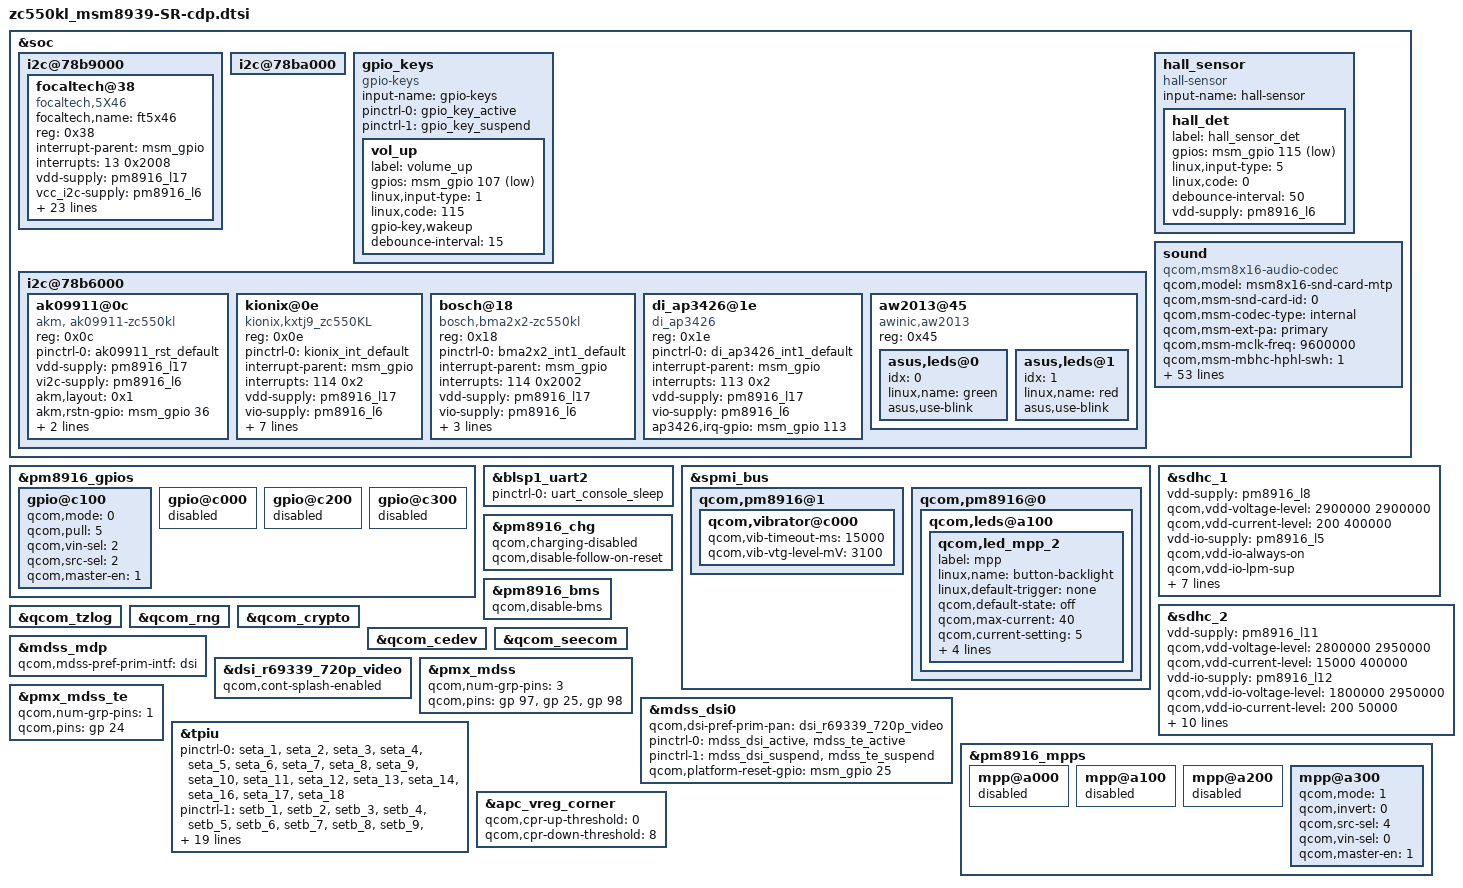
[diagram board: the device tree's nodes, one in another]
/* Copyright (c) 2014-2015, The Linux Foundation. All rights reserved.
 *
 * This program is free software; you can redistribute it and/or modify
 * it under the terms of the GNU General Public License version 2 and
 * only version 2 as published by the Free Software Foundation.
 *
 * This program is distributed in the hope that it will be useful,
 * but WITHOUT ANY WARRANTY; without even the implied warranty of
 * MERCHANTABILITY or FITNESS FOR A PARTICULAR PURPOSE.  See the
 * GNU General Public License for more details.
 */

#include "zc550kl_msm8939-SR-pinctrl.dtsi"
#include "zc550kl_msm8939-SR-camera-sensor-cdp.dtsi"

&soc {
	i2c@78b9000 { /* BLSP1 QUP5 */
		focaltech@38 {
			compatible = "focaltech,5X46";
			focaltech,name = "ft5x46";
			reg = <0x38>;
			interrupt-parent = <&msm_gpio>;
			interrupts = <13 0x2008>;
			vdd-supply = <&pm8916_l17>;
			vcc_i2c-supply = <&pm8916_l6>;
			/* pins used by touchscreen */
			pinctrl-names = "pmx_ts_active","pmx_ts_suspend","pmx_ts_release";
			pinctrl-0 = <&ts_int_active &ts_reset_active>;
			pinctrl-1 = <&ts_int_suspend &ts_reset_suspend>;
			pinctrl-2 = <&ts_release>;
			focaltech,family-id = <0x36>;
			focaltech,reset-gpio = <&msm_gpio 12 0x0>;
			focaltech,irq-gpio = <&msm_gpio 13 0x2008>;
			focaltech,display-coords = <0 0 720 1280>;
			focaltech,panel-coords = <0 0 720 1370>;
			focaltech,button-map= <139 102 158>;
			focaltech,no-force-update;
			focaltech,i2c-pull-up;
			focaltech,group-id = <1>;
			focaltech,hard-reset-delay-ms = <20>;
			focaltech,soft-reset-delay-ms = <200>;
			focaltech,num-max-touches = <5>;
			focaltech,fw-delay-aa-ms = <30>;
			focaltech,fw-delay-55-ms = <30>;
			focaltech,fw-upgrade-id1 = <0x79>;
			focaltech,fw-upgrade-id2 = <0x18>;
			focaltech,fw-delay-readid-ms = <10>;
			focaltech,fw-delay-era-flsh-ms = <2000>;
			focaltech,fw-auto-cal;
			focaltech,ignore-id-check;
		};
	};

	i2c@78ba000 { /* BLSP1 QUP6 */		
		/* ASUS_BSP: wendy_qin  +++*/
		/*nfc-nci@e {
			compatible = "qcom,nfc-nci";
			reg = <0x0e>;
			qcom,irq-gpio = <&msm_gpio 21 0x00>;
			qcom,dis-gpio = <&msm_gpio 20 0x00>;
			qcom,clk-src = "BBCLK2";
			interrupt-parent = <&msm_gpio>;
			interrupts = <21 0>;
			pinctrl-names = "nfc_active","nfc_suspend";
			pinctrl-0 = <&nfc_int_active &nfc_disable_active>;
			pinctrl-1 = <&nfc_int_suspend &nfc_disable_suspend>;
			qcom,clk-gpio = <&pm8916_gpios 2 0>;
			clocks = <&clock_rpm clk_bb_clk2_pin>;
			clock-names = "ref_clk";
		};	*/
		/* ASUS_BSP: wendy_qin  ---*/
	};
	gpio_keys {
		compatible = "gpio-keys";
		input-name = "gpio-keys";
		pinctrl-names = "tlmm_gpio_key_active","tlmm_gpio_key_suspend";
		pinctrl-0 = <&gpio_key_active>;
		pinctrl-1 = <&gpio_key_suspend>;

		vol_up {
			label = "volume_up";
			gpios = <&msm_gpio 107 0x1>;
			linux,input-type = <1>;
			linux,code = <115>;
			gpio-key,wakeup;
			debounce-interval = <15>;
		};
	};

	i2c@78b6000 { /* BLSP1 QUP2 */
		/* ++++  ASUS_BSP alian_shen "add for akm0991" */
		   ak09911@0c {  
		        compatible = "akm, ak09911-zc550kl";
		        reg = <0x0c>;
		        pinctrl-names = "default";
		        pinctrl-0 = <&ak09911_rst_default>;
		        vdd-supply = <&pm8916_l17>;
		        vi2c-supply = <&pm8916_l6>;
		        akm,layout = <0x1>;
		        akm,rstn-gpio = <&msm_gpio 36 0x0>;
		        akm,auto-report ;
		        akm,use-hrtimer ;
		    };    
		    /* -----  ASUS_BSP alian_shen "add for akm0991" */        
        
		/* ++++  ASUS_BSP alian_shen "add for kxtj2-1009" */
		    kionix@0e {
		        compatible = "kionix,kxtj9_zc550KL";
		        reg = <0x0e>;
		        pinctrl-names = "default";
		        pinctrl-0 = <&kionix_int_default>;
		        interrupt-parent = <&msm_gpio>;
		        interrupts = <114 0x2>;
		        vdd-supply = <&pm8916_l17>;
		        vio-supply = <&pm8916_l6>;
		        kionix,min-interval = <10>;
		        kionix,init-interval = <200>;
		        kionix,axis-map-x = <0>;
		        kionix,axis-map-y = <1>;
		        kionix,axis-map-z = <2>;
		        kionix,g-range = <4>;           
		        kionix,res-12bit;
		    };
		    /* -----  ASUS_BSP alian_shen "add for kxtj2-1009" */

		/* ++++  ASUS_BSP alian_shen "add for bma253" */
		bosch@18 { /* Accelerometer sensor */
			compatible = "bosch,bma2x2-zc550kl";
			reg = <0x18>;
			pinctrl-names = "default";
			pinctrl-0 = <&bma2x2_int1_default>;
 			interrupt-parent = <&msm_gpio>;
			interrupts = <114 0x2002>;
 			vdd-supply = <&pm8916_l17>;
 			vio-supply = <&pm8916_l6>;
			bosch,init-interval = <200>;
			bosch,place = <1>;
			bosch,gpio-int1 = <&msm_gpio 114 0x2002>;
			//bosch,gpio-int2 = <&msm_gpio 114 0x2002>; 
 		};
		/* ----  ASUS_BSP alian_shen "add for bma253" */

		 /* ++++  ASUS_BSP alian_shen "add for P/LSensor" */
		    di_ap3426@1e {
		        compatible = "di_ap3426";
		        reg = <0x1e>;
		        pinctrl-names = "default";
		        pinctrl-0 = <&di_ap3426_int1_default>;
		        interrupt-parent = <&msm_gpio>;
		        interrupts = <113 0x2>;//configuration change accordingly such as bus number & pin number
		        vdd-supply = <&pm8916_l17>;
		        vio-supply = <&pm8916_l6>;
		        ap3426,irq-gpio = <&msm_gpio 113 0x02>;
		        /*ap3426,irq-gpio = <&msm_gpio 113 0x2002>;*/
		    };
		    /* ----  ASUS_BSP alian_shen "add for P/LSensor" */
		    
		  aw2013@45 {
            compatible = "awinic,aw2013";
            reg = <0x45>;
            asus,leds@0 {
                status = "okay";
                idx = <0>;
                linux,name = "green";
                //linux,default-trigger = "battery-full";
                asus,use-blink;
             };
            asus,leds@1 {
                status = "okay";
                idx = <1>;
                linux,name = "red";
                //linux,default-trigger = "charging";
                asus,use-blink;
            };
        };

	};
	
	 /*+++  SZ_BSP gauss_li for hall_sersor porting*/
	  hall_sensor {
	    compatible = "hall-sensor";
	    input-name = "hall-sensor";
	    hall_det {
	           label = "hall_sensor_det";
	           gpios = <&msm_gpio 115 0x1>;
	           linux,input-type = <5>;
	           linux,code = <0>;
	           debounce-interval = <50>;
	           vdd-supply = <&pm8916_l6>;
	        };  
	};
	/*---      SZ_BSP gauss_li for hall_sersor porting*/

	sound {
		compatible = "qcom,msm8x16-audio-codec";
		qcom,model = "msm8x16-snd-card-mtp";
		qcom,msm-snd-card-id = <0>;
		qcom,msm-codec-type = "internal";
		qcom,msm-ext-pa = "primary";
		qcom,msm-mclk-freq = <9600000>;
		qcom,msm-mbhc-hphl-swh = <1>;//mei_huang headset detect
		qcom,msm-mbhc-gnd-swh = <0>;
		qcom,msm-hs-micbias-type = "internal";
		qcom,audio-routing =
			"RX_BIAS", "MCLK",
			"SPK_RX_BIAS", "MCLK",
			"INT_LDO_H", "MCLK",
			"MIC BIAS Internal1", "Handset Mic",
			"MIC BIAS Internal2", "Headset Mic",
			"MIC BIAS Internal3", "Secondary Mic",
			"AMIC1", "MIC BIAS Internal1",
			"AMIC2", "MIC BIAS Internal2",
			"AMIC3", "MIC BIAS Internal3";
		pinctrl-names = "cdc_lines_act",
				"cdc_lines_sus",
				"cross_conn_det_act",
				"cross_conn_det_sus",
				"spk_amp_act",
				"spk_amp_sus";//mei_huang config speaker amp
		pinctrl-0 = <&cdc_pdm_lines_act>;
		pinctrl-1 = <&cdc_pdm_lines_sus>;
		pinctrl-2 = <&cross_conn_det_act>;
		pinctrl-3 = <&cross_conn_det_sus>;
		pinctrl-4 = <&spk_amp_act>;//mei_huang config speaker amp
		pinctrl-5 = <&spk_amp_sus>;//mei_huang config speaker amp
		#qcom,cdc-us-euro-gpios = <&msm_gpio 120 0>;//mei_huang gpio 120 is camera gpio,audio can't use it.
		asoc-platform = <&pcm0>, <&pcm1>, <&voip>, <&voice>,
				<&loopback>, <&compress>, <&hostless>,
				<&afe>, <&lsm>, <&routing>, <&lpa>;
		asoc-platform-names = "msm-pcm-dsp.0", "msm-pcm-dsp.1",
				"msm-voip-dsp", "msm-pcm-voice", "msm-pcm-loopback",
				"msm-compress-dsp", "msm-pcm-hostless", "msm-pcm-afe",
				"msm-lsm-client", "msm-pcm-routing", "msm-pcm-lpa";
		asoc-cpu = <&dai_pri_auxpcm>, <&dai_hdmi>, <&dai_mi2s0>, <&dai_mi2s1>,
				<&dai_mi2s2>, <&dai_mi2s3>, <&sb_0_rx>, <&sb_0_tx>,
				<&sb_1_rx>, <&sb_1_tx>, <&sb_3_rx>, <&sb_3_tx>,
				<&sb_4_rx>, <&sb_4_tx>, <&sb_5_tx>, <&bt_sco_rx>,
				<&bt_sco_tx>, <&bt_a2dp_rx>,
				<&int_fm_rx>, <&int_fm_tx>, <&afe_pcm_rx>,
				<&afe_pcm_tx>, <&afe_proxy_rx>, <&afe_proxy_tx>,
				<&incall_record_rx>, <&incall_record_tx>, <&incall_music_rx>,
				<&incall_music_2_rx>;
		asoc-cpu-names = "msm-dai-q6-auxpcm.1", "msm-dai-q6-hdmi.8", "msm-dai-q6-mi2s.0",
				"msm-dai-q6-mi2s.1", "msm-dai-q6-mi2s.2",
				"msm-dai-q6-mi2s.3", "msm-dai-q6-dev.16384",
				"msm-dai-q6-dev.16385", "msm-dai-q6-dev.16386",
				"msm-dai-q6-dev.16387", "msm-dai-q6-dev.16390",
				"msm-dai-q6-dev.16391", "msm-dai-q6-dev.16392",
				"msm-dai-q6-dev.16393", "msm-dai-q6-dev.16395",
				"msm-dai-q6-dev.12288", "msm-dai-q6-dev.12289",
				"msm-dai-q6-dev.12290", "msm-dai-q6-dev.12292",
				"msm-dai-q6-dev.12293",	"msm-dai-q6-dev.224",
				"msm-dai-q6-dev.225", "msm-dai-q6-dev.241",
				"msm-dai-q6-dev.240", "msm-dai-q6-dev.32771",
				"msm-dai-q6-dev.32772", "msm-dai-q6-dev.32773",
				"msm-dai-q6-dev.32770";
		asoc-codec = <&stub_codec>, <&pm8916_tombak_dig>;
		asoc-codec-names = "msm-stub-codec.1", "tombak_codec";
		spk_amp = <&msm_gpio 112 0x0>;//mei_huang config speaker amp gpio 
	};
};

&pm8916_gpios {
	gpio@c100 { /* GPIO 2 */
		/* NFC_CLK_REQ */
		qcom,mode = <0>; /* QPNP_PIN_MODE_DIG_IN */
		qcom,pull = <5>; /* QPNP_PIN_PULL_NO */
		qcom,vin-sel = <2>; /* QPNP_PIN_VIN2 */
		qcom,src-sel = <2>; /* QPNP_PIN_SEL_FUNC_1 */
		qcom,master-en = <1>;
	};
};

&blsp1_uart2 {
	status = "ok";
	pinctrl-names = "default";
	pinctrl-0 = <&uart_console_sleep>;
};

&spmi_bus {
	qcom,pm8916@1 {
		qcom,vibrator@c000 {
			status = "okay";
			qcom,vib-timeout-ms = <15000>;
			qcom,vib-vtg-level-mV = <3100>;
		};
	};

	qcom,pm8916@0 {
		qcom,leds@a100 {
			status = "okay";
			qcom,led_mpp_2 {
				label = "mpp";
				linux,name = "button-backlight";
				linux,default-trigger = "none";
				qcom,default-state = "off";
				qcom,max-current = <40>;
				qcom,current-setting = <5>;
				qcom,id = <6>;
				qcom,mode = "manual";
				qcom,source-sel = <1>;
				qcom,mode-ctrl = <0x60>;
			};
		};
	};
};

&sdhc_1 {
	vdd-supply = <&pm8916_l8>;
	qcom,vdd-voltage-level = <2900000 2900000>;
	qcom,vdd-current-level = <200 400000>;

	vdd-io-supply = <&pm8916_l5>;
	qcom,vdd-io-always-on;
	qcom,vdd-io-lpm-sup;
	qcom,vdd-io-voltage-level = <1800000 1800000>;
	qcom,vdd-io-current-level = <200 60000>;

	pinctrl-names = "active", "sleep";
	pinctrl-0 = <&sdc1_clk_on &sdc1_cmd_on &sdc1_data_on>;
	pinctrl-1 = <&sdc1_clk_off &sdc1_cmd_off &sdc1_data_off>;

	qcom,nonremovable;

	status = "ok";
};

&sdhc_2 {
	vdd-supply = <&pm8916_l11>;
	qcom,vdd-voltage-level = <2800000 2950000>;
	qcom,vdd-current-level = <15000 400000>;

	vdd-io-supply = <&pm8916_l12>;
	qcom,vdd-io-voltage-level = <1800000 2950000>;
	qcom,vdd-io-current-level = <200 50000>;

	pinctrl-names = "active", "sleep";
	pinctrl-0 = <&sdc2_clk_on &sdc2_cmd_on &sdc2_data_on &sdc2_cd_on>;
	pinctrl-1 = <&sdc2_clk_off &sdc2_cmd_off &sdc2_data_off &sdc2_cd_off>;

	#address-cells = <0>;
	interrupt-parent = <&sdhc_2>;
	interrupts = <0 1 2>;
	#interrupt-cells = <1>;
	interrupt-map-mask = <0xffffffff>;
	interrupt-map = <0 &intc 0 125 0
			1 &intc 0 221 0
			2 &msm_gpio 38 0>;
	interrupt-names = "hc_irq", "pwr_irq", "status_irq";
	cd-gpios = <&msm_gpio 38 0x1>;

	status = "ok";
};

&pm8916_chg {
	status = "ok";
	qcom,charging-disabled;
	qcom,disable-follow-on-reset;
};

&pm8916_bms {
	status = "ok";
	qcom,disable-bms;
};

&qcom_tzlog {
	status = "okay";
};

&qcom_rng {
	status = "okay";
};

&qcom_crypto {
	status = "okay";
};

&qcom_cedev {
	status = "okay";
};

&qcom_seecom {
	status = "okay";
};


#include "dsi-panel-r69339-720p-video.dtsi"

&mdss_mdp {
	qcom,mdss-pref-prim-intf = "dsi";
};

&dsi_r69339_720p_video {
       qcom,cont-splash-enabled;
};

&pmx_mdss {
	qcom,num-grp-pins = <3>;
	qcom,pins = <&gp 97>, <&gp 25>, <&gp 98>;
};

&pmx_mdss_te {
	qcom,num-grp-pins = <1>;
	qcom,pins = <&gp 24>;
};

&mdss_dsi0 {
	qcom,dsi-pref-prim-pan = <&dsi_r69339_720p_video>;
	pinctrl-names = "mdss_default", "mdss_sleep";
	pinctrl-0 = <&mdss_dsi_active &mdss_te_active>;
	pinctrl-1 = <&mdss_dsi_suspend &mdss_te_suspend>;

	/*qcom,platform-enable-gpio = <&msm_gpio 97 0>;*/
	qcom,platform-reset-gpio = <&msm_gpio 25 0>;
	/*qcom,platform-bklight-en-gpio = <&msm_gpio 21 0>;*/
};


&pm8916_mpps {
	mpp@a000 { /* MPP 1 */
		/* VDD_PX */
		status = "disabled";
	};

	mpp@a100 { /* MPP 2 */
		/* HR LED */
		status = "disabled";
	};

	mpp@a200 { /* MPP 3 */
		/* VREF DAC */
		status = "disabled";
	};

	mpp@a300 { /* MPP 4 */
		/* Backlight PWM */
		qcom,mode = <1>;		/* Digital output */
		qcom,invert = <0>;		/* Disable invert */
		qcom,src-sel = <4>;		/* DTEST1 */
		qcom,vin-sel = <0>;		/* VPH_PWR */
		qcom,master-en = <1>;		/* Enable MPP */
	};
};

&pm8916_gpios {
	gpio@c000 { /* GPIO 1 */
		/* Battery UICC Alarm */
		status = "disabled";
	};

	gpio@c100 { /* GPIO 2 */
		/* NFC_CLK_REQ */
		qcom,mode = <0>; /* QPNP_PIN_MODE_DIG_IN */
		qcom,pull = <5>; /* QPNP_PIN_PULL_NO */
		qcom,vin-sel = <2>; /* QPNP_PIN_VIN2 */
		qcom,src-sel = <2>; /* QPNP_PIN_SEL_FUNC_1 */
		qcom,master-en = <1>;
	};

	gpio@c200 { /* GPIO 3 */
		/* External regulator control for WTR */
		status = "disabled";
	};

	gpio@c300 { /* GPIO 4 */
		/* External regulator control for APC */
		status = "disabled";
	};
};

/* CoreSight */
&tpiu {
	pinctrl-names = "seta-pctrl", "setb-pctrl", "sdcard", "trace",
			"swduart", "swdtrc", "jtag", "spmi";
	/* Mictor */
	//mei_huang remove seta_15,gpio 112 is audio speaker amp GPIO,others can't use it.
	pinctrl-0 = <&seta_1 &seta_2 &seta_3 &seta_4 &seta_5 &seta_6 &seta_7
		     &seta_8 &seta_9 &seta_10 &seta_11 &seta_12 &seta_13
		     &seta_14 &seta_16 &seta_17 &seta_18>;
	pinctrl-1 = <&setb_1 &setb_2 &setb_3 &setb_4 &setb_5 &setb_6 &setb_7
		     &setb_8 &setb_9 &setb_10 &setb_11 &setb_12 &setb_13
		     &setb_14 &setb_15 &setb_16 &setb_17 &setb_18>;
	/* NIDnT */
	pinctrl-2 = <&qdsd_clk_sdcard &qdsd_cmd_sdcard
		    &qdsd_data0_sdcard &qdsd_data1_sdcard
		    &qdsd_data2_sdcard &qdsd_data3_sdcard>;
	pinctrl-3 = <&qdsd_clk_trace &qdsd_cmd_trace
		    &qdsd_data0_trace &qdsd_data1_trace
		    &qdsd_data2_trace &qdsd_data3_trace>;
	pinctrl-4 = <&qdsd_cmd_swduart &qdsd_data0_swduart
		    &qdsd_data1_swduart &qdsd_data2_swduart
		    &qdsd_data3_swduart>;
	pinctrl-5 = <&qdsd_clk_swdtrc &qdsd_cmd_swdtrc
		    &qdsd_data0_swdtrc &qdsd_data1_swdtrc
		    &qdsd_data2_swdtrc &qdsd_data3_swdtrc>;
	pinctrl-6 = <&qdsd_cmd_jtag &qdsd_data0_jtag
		    &qdsd_data1_jtag &qdsd_data2_jtag
		    &qdsd_data3_jtag>;
	pinctrl-7 = <&qdsd_clk_spmi &qdsd_cmd_spmi
		    &qdsd_data0_spmi &qdsd_data3_spmi>;
};

&apc_vreg_corner {
		qcom,cpr-up-threshold = <0>;
		qcom,cpr-down-threshold = <8>;
};
